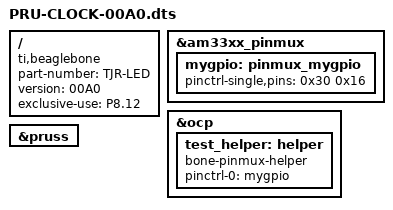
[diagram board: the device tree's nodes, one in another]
/*
        TJR-LED
*/
/dts-v1/;
/plugin/;
 

/ {
  compatible = "ti,beaglebone", "ti,beaglebone-black";
 
  /* identification */
  part-number = "TJR-LED";
  version = "00A0";
  exclusive-use =
    "P8.12";
 
  fragment@0 {
    target = <&am33xx_pinmux>;
    __overlay__ {
      mygpio: pinmux_mygpio{
        pinctrl-single,pins = <
          0x30 0x16
          >;
      };
    };
  };
 
  fragment@1 {
    target = <&ocp>;
    __overlay__ {
      test_helper: helper {
        compatible = "bone-pinmux-helper";
        pinctrl-names = "default";
        pinctrl-0 = <&mygpio>;
        status = "okay";
      };
    };
  };
 
  fragment@2{
  target = <&pruss>;
    __overlay__ {
      status = "okay";
    };
  };
};
